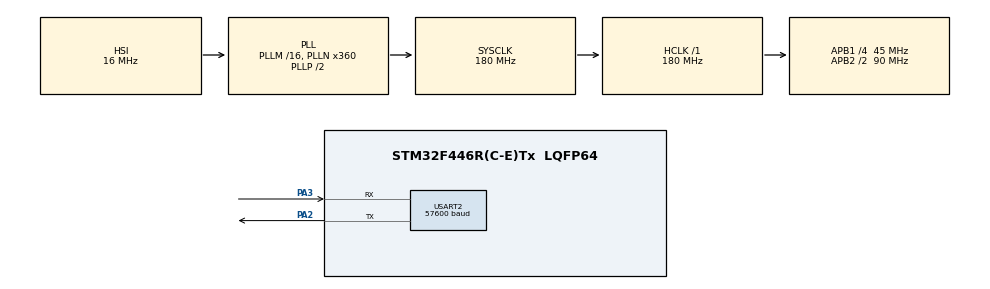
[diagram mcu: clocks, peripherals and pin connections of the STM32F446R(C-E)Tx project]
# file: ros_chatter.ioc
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Mcu.Family=STM32F4
Dma.USART2_TX.1.Priority=DMA_PRIORITY_HIGH
RCC.CortexFreq_Value=180000000
Dma.USART2_TX.1.FIFOMode=DMA_FIFOMODE_DISABLE
Dma.USART2_TX.1.MemInc=DMA_MINC_ENABLE
Dma.USART2_RX.0.Direction=DMA_PERIPH_TO_MEMORY
RCC.APB1CLKDivider=RCC_HCLK_DIV4
Dma.USART2_TX.1.PeriphDataAlignment=DMA_PDATAALIGN_BYTE
NVIC.USART2_IRQn=true\:0\:0\:false\:false\:true\:true\:true
USART2.BaudRate=57600
RCC.SYSCLKSource=RCC_SYSCLKSOURCE_PLLCLK
ProjectManager.StackSize=0x400
Dma.USART2_RX.0.Mode=DMA_NORMAL
PA3.Mode=Asynchronous
ProjectManager.TargetToolchain=Makefile
NVIC.DMA1_Stream5_IRQn=true\:0\:0\:false\:false\:true\:false\:true
Dma.USART2_RX.0.Priority=DMA_PRIORITY_HIGH
Dma.USART2_RX.0.PeriphDataAlignment=DMA_PDATAALIGN_BYTE
RCC.HCLKFreq_Value=180000000
RCC.APB2TimFreq_Value=180000000
Dma.USART2_TX.1.Mode=DMA_NORMAL
RCC.USBFreq_Value=180000000
RCC.AHBFreq_Value=180000000
Dma.USART2_TX.1.PeriphInc=DMA_PINC_DISABLE
board=custom
RCC.VCOOutputFreq_Value=360000000
Dma.USART2_TX.1.Direction=DMA_MEMORY_TO_PERIPH
RCC.APB2Freq_Value=90000000
Dma.USART2_RX.0.MemDataAlignment=DMA_MDATAALIGN_BYTE
Dma.USART2_TX.1.Instance=DMA1_Stream6
Dma.USART2_RX.0.Instance=DMA1_Stream5
Dma.USART2_RX.0.MemInc=DMA_MINC_ENABLE
Mcu.Name=STM32F446R(C-E)Tx
PA2.Signal=USART2_TX
RCC.SYSCLKFreq_VALUE=180000000
Mcu.Package=LQFP64
Dma.USART2_RX.0.PeriphInc=DMA_PINC_DISABLE
USART2.VirtualMode=VM_ASYNC
Dma.USART2_RX.0.FIFOMode=DMA_FIFOMODE_DISABLE
ProjectManager.HeapSize=0x200
NVIC.PriorityGroup=NVIC_PRIORITYGROUP_4
RCC.APB2CLKDivider=RCC_HCLK_DIV2
RCC.PLLN=360
Dma.Request1=USART2_TX
RCC.APB1TimFreq_Value=90000000
PA2.Mode=Asynchronous
Dma.USART2_TX.1.MemDataAlignment=DMA_MDATAALIGN_BYTE
Dma.Request0=USART2_RX
NVIC.DMA1_Stream6_IRQn=true\:0\:0\:false\:false\:true\:false\:true
RCC.APB1Freq_Value=45000000
PA3.Signal=USART2_RX

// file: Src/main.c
/* USER CODE BEGIN Header */
/**
  ******************************************************************************
  * @file           : main.c
  * @brief          : Main program body
  ******************************************************************************
  * @attention
  *
  * <h2><center>&copy; Copyright (c) 2020 STMicroelectronics.
  * All rights reserved.</center></h2>
  *
  * This software component is licensed by ST under BSD 3-Clause license,
  * the "License"; You may not use this file except in compliance with the
  * License. You may obtain a copy of the License at:
  *                        opensource.org/licenses/BSD-3-Clause
  *
  ******************************************************************************
  */
/* USER CODE END Header */
#include "main.h"
#include "dma.h"
#include "usart.h"
#include "gpio.h"

/* USER CODE BEGIN Includes */
#include <mainpp.h>
/* USER CODE END Includes */

void SystemClock_Config(void);

int main(void)
{

  /* MCU Configuration--------------------------------------------------------*/

  /* Reset of all peripherals, Initializes the Flash interface and the Systick. */
  HAL_Init();

  /* Configure the system clock */
  SystemClock_Config();

  /* Initialize all configured peripherals */
  MX_GPIO_Init();
  MX_DMA_Init();
  MX_USART2_UART_Init();
  /* USER CODE BEGIN 2 */
  setup();
  /* USER CODE END 2 */

  /* Infinite loop */
  while (1)
  {

    /* USER CODE BEGIN 3 */
    loop();
    HAL_Delay(500);
  }
  /* USER CODE END 3 */
}

void SystemClock_Config(void)
{
  RCC_OscInitTypeDef RCC_OscInitStruct = {0};
  RCC_ClkInitTypeDef RCC_ClkInitStruct = {0};

  /** Configure the main internal regulator output voltage
  */
  __HAL_RCC_PWR_CLK_ENABLE();
  __HAL_PWR_VOLTAGESCALING_CONFIG(PWR_REGULATOR_VOLTAGE_SCALE1);
  /** Initializes the RCC Oscillators according to the specified parameters
  * in the RCC_OscInitTypeDef structure.
  */
  RCC_OscInitStruct.OscillatorType = RCC_OSCILLATORTYPE_HSI;
  RCC_OscInitStruct.HSIState = RCC_HSI_ON;
  RCC_OscInitStruct.HSICalibrationValue = RCC_HSICALIBRATION_DEFAULT;
  RCC_OscInitStruct.PLL.PLLState = RCC_PLL_ON;
  RCC_OscInitStruct.PLL.PLLSource = RCC_PLLSOURCE_HSI;
  RCC_OscInitStruct.PLL.PLLM = 16;
  RCC_OscInitStruct.PLL.PLLN = 360;
  RCC_OscInitStruct.PLL.PLLP = RCC_PLLP_DIV2;
  RCC_OscInitStruct.PLL.PLLQ = 2;
  RCC_OscInitStruct.PLL.PLLR = 2;
  if (HAL_RCC_OscConfig(&RCC_OscInitStruct) != HAL_OK)
  {
    Error_Handler();
  }
  /** Activate the Over-Drive mode
  */
  if (HAL_PWREx_EnableOverDrive() != HAL_OK)
  {
    Error_Handler();
  }
  /** Initializes the CPU, AHB and APB buses clocks
  */
  RCC_ClkInitStruct.ClockType = RCC_CLOCKTYPE_HCLK|RCC_CLOCKTYPE_SYSCLK
                              |RCC_CLOCKTYPE_PCLK1|RCC_CLOCKTYPE_PCLK2;
  RCC_ClkInitStruct.SYSCLKSource = RCC_SYSCLKSOURCE_PLLCLK;
  RCC_ClkInitStruct.AHBCLKDivider = RCC_SYSCLK_DIV1;
  RCC_ClkInitStruct.APB1CLKDivider = RCC_HCLK_DIV4;
  RCC_ClkInitStruct.APB2CLKDivider = RCC_HCLK_DIV2;

  if (HAL_RCC_ClockConfig(&RCC_ClkInitStruct, FLASH_LATENCY_5) != HAL_OK)
  {
    Error_Handler();
  }
}

void Error_Handler(void)
{
}

/************************ (C) COPYRIGHT STMicroelectronics *****END OF FILE****/
